# MINI51AN_v1 register map
File version: 1.0
Registers are 32-bit, read-write, reset 0x0 unless marked. A register's access mark holds for its fields unless they carry their own. Offsets are from the block's base; [hi:lo] are bit positions.

## GCR — GCR Register Map
Base 0x50000000
0x00 PDID ro reset not defined — Part Device Identification Number Register
  [31:0] PDID — Product Device Identification Number. This register reflects the device part number code. Software can read this register to identify which device is used. For example, the MINI51LBN PDID code is "0x10205100".
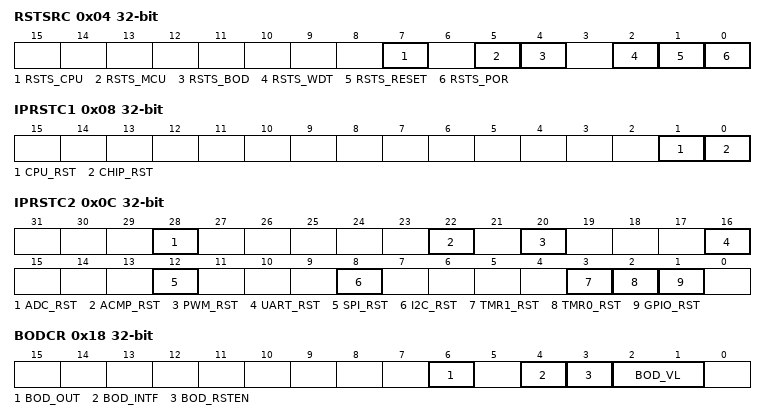
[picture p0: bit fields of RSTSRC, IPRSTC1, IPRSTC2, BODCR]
0x04 RSTSRC (reset mask 0xFFFFFF00) — System Reset Source Register
  [7] RSTS_CPU — The RSTS_CPU flag is set by hardware if software writes CPU_RST (IPRSTC1[1]) with 1 to reset the Cortex-M0 CPU kernel and Flash Memory Controller (FMC). Software can write 1 to clear this bit to zero.
    0=No reset from CPU; 1=The Cortex-M0 CPU kernel and FMC are reset by setting CPU_RST to 1
  [5] RSTS_MCU — The RSTS_MCU flag is set by the "reset signal" from the Cortex-M0 kernel to indicate the previous reset source. Software can write 1 to clear this bit to zero.
    0=No reset from Cortex-M0; 1=The Cortex-M0 had issued the reset signal to reset the system by software writing 1 to bit SYSRESETREQ (AIRCR[2]), Application Interrupt and Reset Control Register, address = 0xE000ED0C) in system control registers of Cortex-M0 kernel
  [4] RSTS_BOD — The RSTS_BOD flag is set by the "reset signal" from the Brown-out Detected module to indicate the previous reset source. Software can write 1 to clear this bit to zero.
    0=No reset from BOD; 1=The Brown-out Detected module had issued the reset signal to reset the system
  [2] RSTS_WDT — The RSTS_WDT flag is set by the "reset signal" from the Watchdog module to indicate the previous reset source. Software can write 1 to clear this bit to zero.
    0=No reset from Watchdog; 1=The Watchdog module had issued the reset signal to reset the system
  [1] RSTS_RESET — The RSTS_RESET flag is set by the "reset signal" from the /RESET pin to indicate the previous reset source. Software can write 1 to clear this bit to zero.
    0=No reset from pin /RESET; 1=The pin /RESET had issued the reset signal to reset the system
  [0] RSTS_POR — The RSTS_POR flag is set by the "reset signal", which is from the Power-On Reset (POR) module or bit CHIP_RST (IPRSTC1[0]) set, to indicate the previous reset source. Software can write 1 to clear this bit to zero.
    0=No reset from POR; 1=The Power-On-Reset (POR) or CHIP_RST=1 had issued the reset signal to reset the system
0x08 IPRSTC1 — IP Reset Control Resister 1
  [1] CPU_RST — CPU Kernel One Shot Reset. Setting this bit will reset the CPU kernel, and this bit will automatically return to 0 after the 2 clock cycles. This bit is the protected bit, programming this needs an open lock sequence, write 0x59, 0x16, 0x88 to address 0x5000_0100 to un-lock this bit. Refer to the register RegLockAddr at address GCR_BA + 0x100.
    0=Normal; 1=Reset CPU
  [0] CHIP_RST — CHIP One Shot Reset. Setting this bit will reset the CHIP, including CPU kernel and all peripherals, and this bit will automatically return to 0 after the 2 clock cycles. The CHIP_RST is the same as the POR reset, and all the chip module is reset and the chip settings from flash are also reload. This bit is the protected bit, and programming this needs an open lock sequence, write 0x59, 0x16, 0x88 to address 0x5000_0100 to un-lock this bit. Refer to the register RegLockAddr at address GCR_BA + 0x100.
    0=Normal; 1=Reset CHIP
0x0C IPRSTC2 — IP Reset Control Resister 2
  [28] ADC_RST — ADC Controller Reset
    0=ADC block normal operation; 1=ADC block reset
  [22] ACMP_RST — ACMP Controller Reset
    0=ACMP block normal operation; 1=ACMP block reset
  [20] PWM_RST — PWM Controller Reset
    0=PWM block normal operation; 1=PWM block reset
  [16] UART_RST — UART Controller Reset
    0=UART normal operation; 1=UART block reset
  [12] SPI_RST — SPI Controller Reset
    0=SPI block normal operation; 1=SPI block reset
  [8] I2C_RST — I2C Controller Reset
    0=I2C normal operation; 1=I2C block reset
  [3] TMR1_RST — Timer1 Controller Reset
    0=Timer1 normal operation; 1=Timer1 block reset
  [2] TMR0_RST — Timer0 Controller Reset
    0=Timer0 normal operation; 1=Timer0 block reset
  [1] GPIO_RST — GPIO (P0~P5) Controller Reset
    0=GPIO normal operation; 1=GPIO reset
0x18 BODCR (reset mask 0xFFFFFFF0) — Brown-out Detector Control Register
  [6] BOD_OUT — Brown-out Detector Output State
    0=Brown-out Detector status output is 0, the detected voltage is higher than BOD_VL setting; 1=Brown-out Detector status output is 1, the detected voltage is lower than BOD_VL setting
  [4] BOD_INTF — Brown-out Detector Interrupt Flag
    0=Brown-out Detector does not detect any voltage draft at VDD down through or up through the voltage of BOD_VL setting; 1=When Brown-out Detector detects the VDD is dropped through the voltage of BOD_VL setting or the VDD is raised up through the voltage of BOD_VL setting, this bit is set to 1 and the Brown-out interrupt is requested if Brown-out interrupt is enabled
  [3] BOD_RSTEN — Brown-out Reset Enable (Initiated and Write-protected bit). When the BOD_EN is enabled and the interrupt is asserted, the interrupt will be kept till the BOD_EN is set to 0. The interrupt for CPU can be blocked by disabling the NVIC in CPU for BOD interrupt or disable the interrupt source by disabling the BOD_EN and then re-enabling the BOD_EN function if the BOD function is required.
    0=Brown-out "INTERRUPT" function Enabled; when the Brown-out Detector function is enable and the detected voltage is lower than the threshold, then assert a signal to interrupt the Cortex-M0 CPU; 1=Brown-out "RESET" function Enabled; when the Brown-out Detector function is enable and the detected voltage is lower than the threshold then assert a signal to reset the chip
  [2:1] BOD_VL — Brown-out Detector Threshold Voltage Selection (Initiated Write-protected bit)
0x1C LDOCR (reset mask 0xFFFF0000) — LDO Control Register
0x20 LDOBPCR — LDO Bypass Control Register
0x24 PORCR (reset mask 0xFFFF0000) — Power-On-Reset Control Register
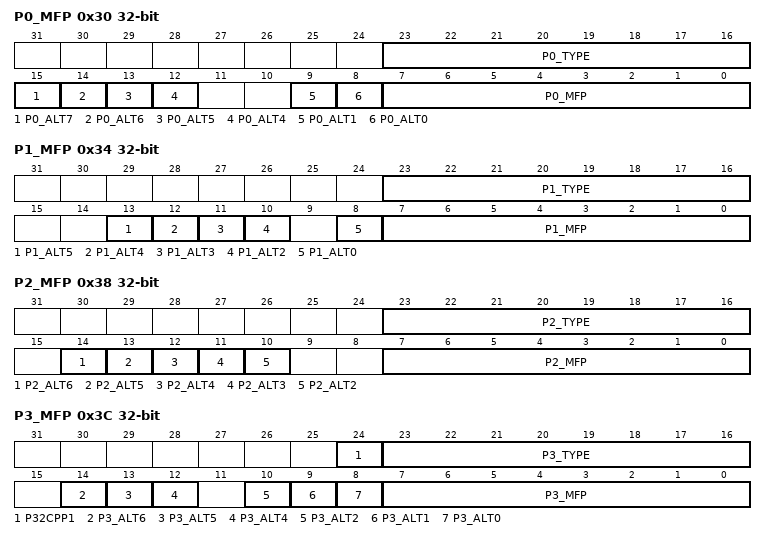
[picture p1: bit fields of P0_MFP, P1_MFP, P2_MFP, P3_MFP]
0x30 P0_MFP — P0 Multiple Function and Input Type Control Register
  [23:16] P0_TYPE — P0[7:0] Input Schmitt Trigger Function Enable
    0=P0[7:0] I/O input Schmitt Trigger function Disabled; 1=P0[7:0] I/O input Schmitt Trigger function Enabled
  [15] P0_ALT7 — P0.7 Alternate Function Selection
  [14] P0_ALT6 — P0.6 Alternate Function Selection
  [13] P0_ALT5 — P0.5 Alternate Function Selection
  [12] P0_ALT4 — P0.4 Alternate Function Selection
  [9] P0_ALT1 — P0.1 Alternate Function Selection
  [8] P0_ALT0 — P0.0 Alternate Function Selection
  [7:0] P0_MFP — P0 Multiple Function Selection. The pin function of P0 depends on P0_MFP and P0_ALT. Refer to P0_ALT Description for details.
0x34 P1_MFP — P1 Multiple Function and Input Type Control Register
  [23:16] P1_TYPE — P1[7:0] Input Schmitt Trigger Function Enable
    0=P1[7:0] I/O input Schmitt Trigger function Disabled; 1=P1[7:0] I/O input Schmitt Trigger function Enabled
  [13] P1_ALT5 — P1.5 Alternate Function Selection
  [12] P1_ALT4 — P1.4 Alternate Function Selection
  [11] P1_ALT3 — P1.3 Alternate Function Selection
  [10] P1_ALT2 — P1.2 Alternate Function Selection
  [8] P1_ALT0 — P1.0 Alternate Function Selection
  [7:0] P1_MFP — P1 Multiple Function Selection. The pin function of P1 depends on P1_MFP and P1_ALT. Refer to P1_ALT Description for details.
0x38 P2_MFP — P2 Multiple Function and Input Type Control Register
  [23:16] P2_TYPE — P2[7:0] Input Schmitt Trigger Function Enable
    0=P2[7:0] I/O input Schmitt Trigger function Disabled; 1=P2[7:0] I/O input Schmitt Trigger function Enabled
  [14] P2_ALT6 — P2.6 Alternate Function Selection
  [13] P2_ALT5 — P2.5 Alternate Function Selection
  [12] P2_ALT4 — P2.4 Alternate Function Selection
  [11] P2_ALT3 — P2.3 Alternate Function Selection
  [10] P2_ALT2 — P2.2 Alternate Function Selection
  [7:0] P2_MFP — P2 Multiple Function Selection. The pin function of P2 depends on P2_MFP and P2_ALT. Refer to P2_ALT Description for details.
0x3C P3_MFP — P3 Multiple Function and Input Type Control Register
  [24] P32CPP1 — P3.2 Alternate Function Selection Extension
    0=P3.2 is set by P3_ALT[2] and P3_MFP[2]; 1=P3.2 is set to CPP1 of ACMP1
  [23:16] P3_TYPE — P3[7:0] Input Schmitt Trigger Function Enable
    0=P3[7:0] I/O input Schmitt Trigger function Disabled; 1=P3[7:0] I/O input Schmitt Trigger function Enabled
  [14] P3_ALT6 — P3.6 Alternate Function Selection
  [13] P3_ALT5 — P3.5 Alternate Function Selection
  [12] P3_ALT4 — P3.4 Alternate Function Selection
  [10] P3_ALT2 — P3.2 Alternate Function Selection
  [9] P3_ALT1 — P3.1 Alternate Function Selection
  [8] P3_ALT0 — P3.0 Alternate Function Selection
  [7:0] P3_MFP — P3 Multiple Function Selection. The pin function of P3 depends on P3_MFP and P3_ALT. Refer to P3_ALT Description for details.
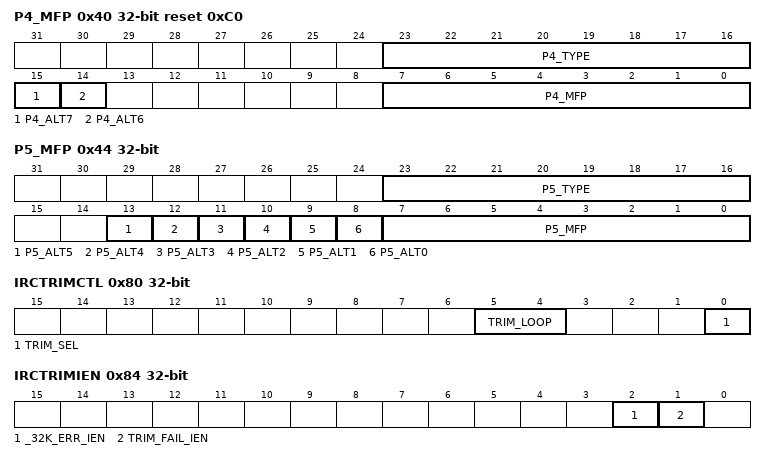
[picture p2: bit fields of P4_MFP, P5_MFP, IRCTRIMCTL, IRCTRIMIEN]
0x40 P4_MFP reset 0xC0 — P4 Multiple Function and Input Type Control Register
  [23:16] P4_TYPE — P4[7:0] Input Schmitt Trigger Function Enable
    0=P4[7:0] I/O input Schmitt Trigger function Disabled; 1=P4[7:0] I/O input Schmitt Trigger function Enabled
  [15] P4_ALT7 — P4.7 Alternate Function Selection
  [14] P4_ALT6 — P4.6 Alternate Function Selection
  [7:0] P4_MFP — P4 Multiple Function Selection. The pin function of P4 depends on P4_MFP and P4_ALT. Refer to P4_ALT Description for details.
0x44 P5_MFP — P5 Multiple Function and Input Type Control Register
  [23:16] P5_TYPE — P5[7:0] Input Schmitt Trigger Function Enable
    0=P5[7:0] I/O input Schmitt Trigger function Disabled; 1=P5[7:0] I/O input Schmitt Trigger function Enabled
  [13] P5_ALT5 — P5.5 Alternate Function Selection
  [12] P5_ALT4 — P5.4 Alternate Function Selection
  [11] P5_ALT3 — P5.3 Alternate Function Selection
  [10] P5_ALT2 — P5.2 Alternate Function Selection
  [9] P5_ALT1 — P5.1 Alternate Function Selection
  [8] P5_ALT0 — P5.0 Alternate Function Selection
  [7:0] P5_MFP — P5 Multiple Function Selection. The pin function of P5 depends on P5_MFP and P5_ALT. Refer to P5_ALT Description for details.
0x80 IRCTRIMCTL — HIRC Trim Control Register
  [5:4] TRIM_LOOP — Trim Calculation Loop. This field defines trim value calculation based on the number of LXT clock. For example, if TRIM_LOOP is set as "00", auto trim circuit will calculate trim value based on the average frequency difference in 4 LXT clock. This field also defines how many times the auto trim circuit will try to update the HFIRC trim value before the frequency of HFIRC is locked. Once the HFIRC is locked, the internal trim value update counter will be reset. If the trim value update counter reaches this limitation value and frequency of HFIRC is still not locked, the auto trim operation will be disabled and TRIM_SEL will be cleared to 0.
    0=Trim value calculation is based on average difference in 4 LXT clock and trim retry count limitation is 64; 1=Trim value calculation is based on average difference in 8 LXT clock and trim retry count limitation is 128; 2=Trim value calculation is based on average difference in 16 LXT clock and trim retry count limitation is 256; 3=Trim value calculation is based on average difference in 32 LXT clock and trim retry count limitation is 512
  [0] TRIM_SEL — Trim Frequency Selection. This bit is to enable the HFIRC auto trim. When setting this bit to 1, the HFIRC auto trim function will trim HFIRC to 22.1184 MHz automatically based on the LXT reference clock. During auto trim operation, if LXT clock error is detected or trim retry limitation count reached, this field will be cleared to 0 automatically.
    0=HFIRC auto trim function Disabled; 1=HFIRC auto trim function Enabled and HFIRC trimmed to 22.1184 MHz
0x84 IRCTRIMIEN — HIRC Trim Interrupt Enable Register
  [2] _32K_ERR_IEN — LXT Clock Error Interrupt Enable. This bit controls if CPU could get an interrupt while LXT clock is inaccurate during auto trim operation. If this bit is high, and 32K_ERR_INT is set during auto trim operation, an interrupt will be triggered to notify the LXT clock frequency is inaccurate.
    0=32K_ERR_INT status Disabled to trigger an interrupt to CPU; 1=32K_ERR_INT status Enabled to trigger an interrupt to CPU
  [1] TRIM_FAIL_IEN — Trim Failure Interrupt Enable. This bit controls if an interrupt will be triggered while HFIRC trim value update limitation count is reached and HFIRC frequency is still not locked on target frequency set by TRIM_SEL. If this bit is high and TRIM_FAIL_INT is set during auto trim operation, an interrupt will be triggered to notify that HFIRC trim value update limitation count is reached.
    0=TRIM_FAIL_INT status Disabled to trigger an interrupt to CPU; 1=TRIM_FAIL_INT status Enabled to trigger an interrupt to CPU
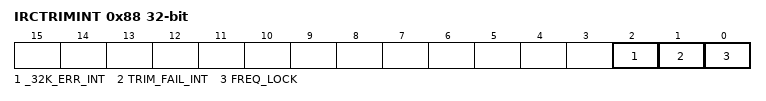
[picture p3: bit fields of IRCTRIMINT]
0x88 IRCTRIMINT — HIRC Trim Interrupt Status Register
  [2] _32K_ERR_INT — LXT Clock Error Interrupt Status. This bit indicates that LXT clock frequency is inaccuracy. Once this bit is set, the auto trim operation stopped and TRIM_SEL will be cleared to 0 by hardware automatically. If this bit is set and 32K_ERR_IEN is high, an interrupt will be triggered to notify the LXT clock frequency is inaccuracy. Software can write 1 to clear this bit to zero.
    0=LXT clock frequency is accuracy; 1=LXT clock frequency is inaccuracy
  [1] TRIM_FAIL_INT — Trim Failure Interrupt Status. This bit indicates that HFIRC trim value update limitation count reached and HIRC clock frequency still doesn't lock. Once this bit is set, the auto trim operation stopped and TRIM_SEL will be cleared to 0 by hardware automatically. If this bit is set and TRIM_FAIL_IEN is high, an interrupt will be triggered to notify that HFIRC trim value update limitation count was reached. Software can write 1 to clear this bit to zero.
    0=Trim value update limitation count is not reached; 1=Trim value update limitation count is reached and HFIRC frequency is still not locked
  [0] FREQ_LOCK — HIRC Frequency Lock Status. This bit indicates the HIRC frequency lock. This is a status bit and doesn't trigger any interrupt.
0x100 RegLockAddr — Register Lock Key Address Register
  [0] RegUnLock — The Protected registers are: IPRSTC1 - address 0x5000_0008 (IP reset control register 1). BODCR - address 0x5000_0018 (Brown-out detector control register). LDOCR - address 0x5000_001C (LDO control register). PORCR - address 0x5000_0024 (Power-On-Reset control register). PWRCON - address 0x5000_0200 (bit[6] is not protected for power wake-up interrupt clear). APBCLK[0] - address 0x5000_0208 (Watchdog clock enable). CLKSEL0 - address 0x5000_0210 (HCLK and CPU STCLK clock source select). CLKSEL1[1:0] - address 0x5000_0214 (Watchdog clock source select). NMI_SEL[8] - address 0x5000_380 (NMI interrupt source enable). ISPCON - address 0x5000_C000 (Flash ISP control register). WTCR - address 0x4000_4000 (Watchdog Timer control register)
    0=Protected registers are locked. Any write to the target register is ignored; 1=Protected registers are Unlock
